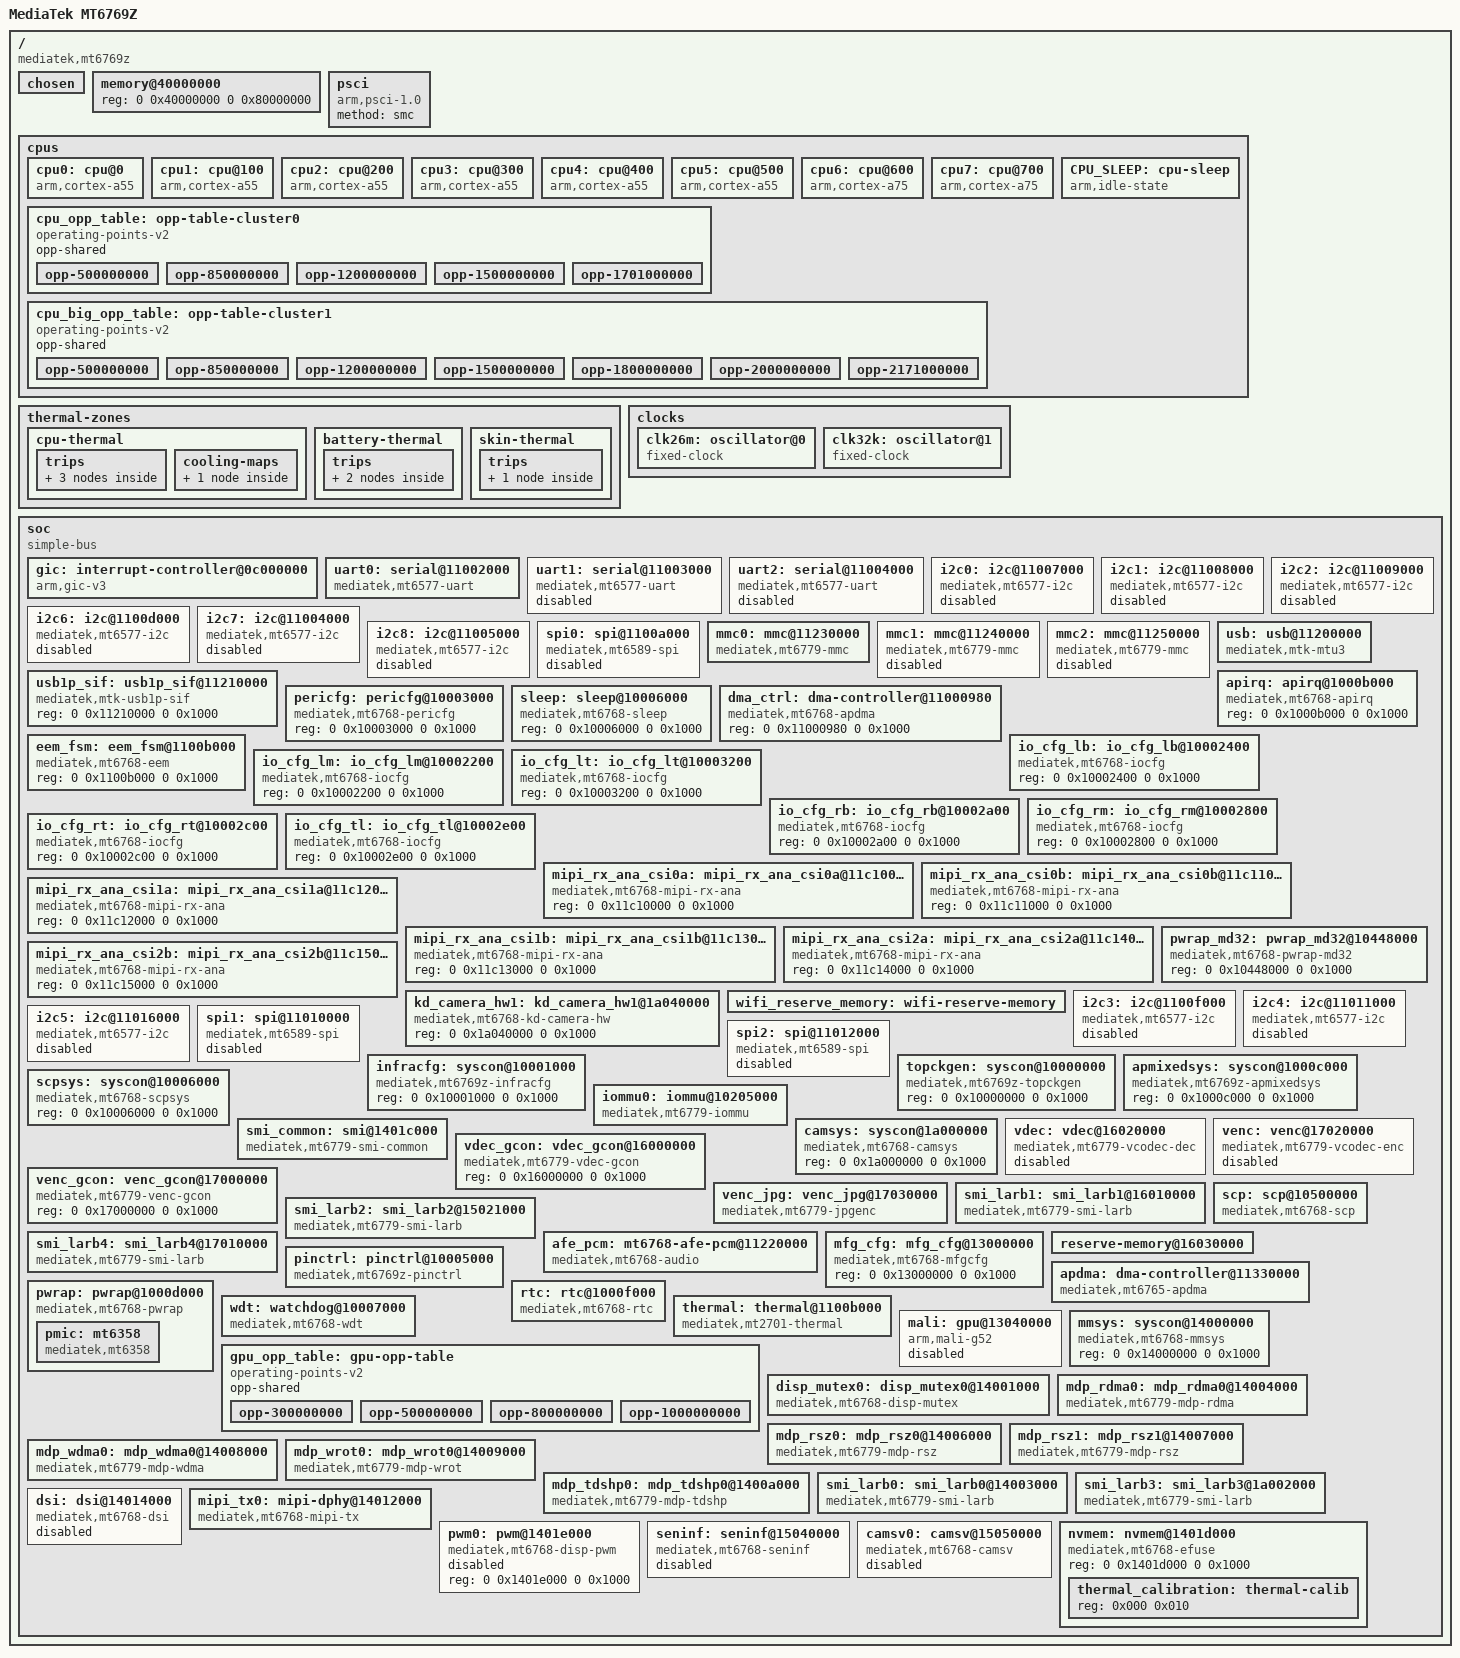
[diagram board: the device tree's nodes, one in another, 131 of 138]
// SPDX-License-Identifier: GPL-2.0
/*
 * MediaTek MT6768/MT6769/MT6769Z SoC device tree source include
 */

#include <dt-bindings/interrupt-controller/arm-gic.h>
#include <dt-bindings/interrupt-controller/irq.h>
#include <dt-bindings/clock/mt6769-clk.h>
#include <dt-bindings/gpio/gpio.h>
#include <dt-bindings/thermal/thermal.h>

/ {
	model = "MediaTek MT6769Z";
	compatible = "mediatek,mt6769z", "mediatek,mt6769", "mediatek,mt6768";
	interrupt-parent = <&gic>;
	#address-cells = <2>;
	#size-cells = <2>;

	chosen {
		bootargs = "console=ttyS0,921600n1 earlycon=uart8250,mmio32,0x11002000,921600n8";
		stdout-path = "uart0:921600n8";
	};

	memory@40000000 {
		device_type = "memory";
		reg = <0 0x40000000 0 0x80000000>;
	};

	psci {
		compatible = "arm,psci-1.0";
		method = "smc";
	};

	cpus {
		#address-cells = <1>;
		#size-cells = <0>;

		cpu0: cpu@0 {
			device_type = "cpu";
			compatible = "arm,cortex-a55";
			reg = <0x000>;
			enable-method = "psci";
			cpu-idle-states = <&CPU_SLEEP>;
			operating-points-v2 = <&cpu_opp_table>;
			#cooling-cells = <2>;
		};
		cpu1: cpu@100 {
			device_type = "cpu";
			compatible = "arm,cortex-a55";
			reg = <0x100>;
			enable-method = "psci";
			cpu-idle-states = <&CPU_SLEEP>;
			operating-points-v2 = <&cpu_opp_table>;
			#cooling-cells = <2>;
		};
		cpu2: cpu@200 {
			device_type = "cpu";
			compatible = "arm,cortex-a55";
			reg = <0x200>;
			enable-method = "psci";
			cpu-idle-states = <&CPU_SLEEP>;
			operating-points-v2 = <&cpu_opp_table>;
			#cooling-cells = <2>;
		};
		cpu3: cpu@300 {
			device_type = "cpu";
			compatible = "arm,cortex-a55";
			reg = <0x300>;
			enable-method = "psci";
			cpu-idle-states = <&CPU_SLEEP>;
			operating-points-v2 = <&cpu_opp_table>;
			#cooling-cells = <2>;
		};
		cpu4: cpu@400 {
			device_type = "cpu";
			compatible = "arm,cortex-a55";
			reg = <0x400>;
			enable-method = "psci";
			cpu-idle-states = <&CPU_SLEEP>;
			operating-points-v2 = <&cpu_opp_table>;
			#cooling-cells = <2>;
		};
		cpu5: cpu@500 {
			device_type = "cpu";
			compatible = "arm,cortex-a55";
			reg = <0x500>;
			enable-method = "psci";
			cpu-idle-states = <&CPU_SLEEP>;
			operating-points-v2 = <&cpu_opp_table>;
			#cooling-cells = <2>;
		};
		cpu6: cpu@600 {
			device_type = "cpu";
			compatible = "arm,cortex-a75";
			reg = <0x600>;
			enable-method = "psci";
			cpu-idle-states = <&CPU_SLEEP>;
			operating-points-v2 = <&cpu_big_opp_table>;
			#cooling-cells = <2>;
		};
		cpu7: cpu@700 {
			device_type = "cpu";
			compatible = "arm,cortex-a75";
			reg = <0x700>;
			enable-method = "psci";
			cpu-idle-states = <&CPU_SLEEP>;
			operating-points-v2 = <&cpu_big_opp_table>;
			#cooling-cells = <2>;
		};

		cpu_opp_table: opp-table-cluster0 {
			compatible = "operating-points-v2";
			opp-shared;

			opp-500000000 {
				opp-hz = /bits/ 64 <500000000>;
				opp-microvolt = <850000>;
			};
			opp-850000000 {
				opp-hz = /bits/ 64 <850000000>;
				opp-microvolt = <900000>;
			};
			opp-1200000000 {
				opp-hz = /bits/ 64 <1200000000>;
				opp-microvolt = <950000>;
			};
			opp-1500000000 {
				opp-hz = /bits/ 64 <1500000000>;
				opp-microvolt = <1000000>;
			};
			opp-1701000000 {
				opp-hz = /bits/ 64 <1701000000>;
				opp-microvolt = <1050000>;
			};
		};

		cpu_big_opp_table: opp-table-cluster1 {
			compatible = "operating-points-v2";
			opp-shared;

			opp-500000000 {
				opp-hz = /bits/ 64 <500000000>;
				opp-microvolt = <850000>;
			};
			opp-850000000 {
				opp-hz = /bits/ 64 <850000000>;
				opp-microvolt = <900000>;
			};
			opp-1200000000 {
				opp-hz = /bits/ 64 <1200000000>;
				opp-microvolt = <950000>;
			};
			opp-1500000000 {
				opp-hz = /bits/ 64 <1500000000>;
				opp-microvolt = <1000000>;
			};
			opp-1800000000 {
				opp-hz = /bits/ 64 <1800000000>;
				opp-microvolt = <1050000>;
			};
			opp-2000000000 {
				opp-hz = /bits/ 64 <2000000000>;
				opp-microvolt = <1100000>;
			};
			opp-2171000000 {
				opp-hz = /bits/ 64 <2171000000>;
				opp-microvolt = <1150000>;
			};
		};

		CPU_SLEEP: cpu-sleep {
			compatible = "arm,idle-state";
			arm,psci-suspend-param = <0x00000001>;
			entry-latency-us = <600>;
			exit-latency-us = <600>;
			min-residency-us = <1200>;
		};
	};

	thermal-zones {
		cpu-thermal {
			polling-delay-passive = <250>;
			polling-delay = <1000>;
			thermal-sensors = <&thermal 0>;

			trips {
				cpu_alert0: cpu-alert0 {
					temperature = <70000>;
					hysteresis = <2000>;
					type = "passive";
				};
				cpu_alert1: cpu-alert1 {
					temperature = <85000>;
					hysteresis = <2000>;
					type = "passive";
				};
				cpu_crit: cpu-crit {
					temperature = <115000>;
					hysteresis = <2000>;
					type = "critical";
				};
			};

			cooling-maps {
				map0 {
					trip = <&cpu_alert0>;
					cooling-device = <&cpu0 THERMAL_NO_LIMIT THERMAL_NO_LIMIT>,
							 <&cpu6 THERMAL_NO_LIMIT THERMAL_NO_LIMIT>;
				};
			};
		};

		battery-thermal {
			polling-delay-passive = <250>;
			polling-delay = <1000>;
			thermal-sensors = <&thermal 1>;

			trips {
				battery_alert: battery-alert {
					temperature = <60000>;
					hysteresis = <2000>;
					type = "passive";
				};
				battery_crit: battery-crit {
					temperature = <70000>;
					hysteresis = <2000>;
					type = "critical";
				};
			};
		};

		skin-thermal {
			polling-delay-passive = <500>;
			polling-delay = <2000>;
			thermal-sensors = <&thermal 2>;

			trips {
				skin_alert: skin-alert {
					temperature = <50000>;
					hysteresis = <2000>;
					type = "passive";
				};
			};
		};
	};

	clocks {
		clk26m: oscillator@0 {
			compatible = "fixed-clock";
			#clock-cells = <0>;
			clock-frequency = <26000000>;
			clock-output-names = "clk26m";
		};
		clk32k: oscillator@1 {
			compatible = "fixed-clock";
			#clock-cells = <0>;
			clock-frequency = <32768>;
			clock-output-names = "clk32k";
		};
	};

	soc {
		compatible = "simple-bus";
		#address-cells = <2>;
		#size-cells = <2>;
		ranges;

		gic: interrupt-controller@0c000000 {
			compatible = "arm,gic-v3";
			reg = <0 0x0c000000 0 0x40000>,
			      <0 0x0c040000 0 0x200000>;
			interrupts = <GIC_PPI 9 IRQ_TYPE_LEVEL_HIGH>;
			interrupt-controller;
			#interrupt-cells = <3>;
		};

		uart0: serial@11002000 {
			compatible = "mediatek,mt6577-uart";
			reg = <0 0x11002000 0 0x1000>;
			interrupts = <GIC_SPI 91 IRQ_TYPE_LEVEL_LOW>;
			clocks = <&infracfg CLK_INFRA_UART0>;
			clock-names = "uart";
			status = "okay";
		};

		uart1: serial@11003000 {
			compatible = "mediatek,mt6577-uart";
			reg = <0 0x11003000 0 0x1000>;
			interrupts = <GIC_SPI 92 IRQ_TYPE_LEVEL_LOW>;
			status = "disabled";
		};

		uart2: serial@11004000 {
			compatible = "mediatek,mt6577-uart";
			reg = <0 0x11004000 0 0x1000>;
			interrupts = <GIC_SPI 93 IRQ_TYPE_LEVEL_LOW>;
			status = "disabled";
		};

		i2c0: i2c@11007000 {
			compatible = "mediatek,mt6577-i2c";
			reg = <0 0x11007000 0 0x1000>,
			      <0 0x11c20000 0 0x1000>;
			interrupts = <GIC_SPI 44 IRQ_TYPE_LEVEL_LOW>;
			clocks = <&clk26m>, <&clk26m>;
			clock-names = "main", "dma";
			#address-cells = <1>;
			#size-cells = <0>;
			status = "disabled";
		};

		i2c1: i2c@11008000 {
			compatible = "mediatek,mt6577-i2c";
			reg = <0 0x11008000 0 0x1000>,
			      <0 0x11c30000 0 0x1000>;
			interrupts = <GIC_SPI 45 IRQ_TYPE_LEVEL_LOW>;
			clocks = <&clk26m>, <&clk26m>;
			clock-names = "main", "dma";
			#address-cells = <1>;
			#size-cells = <0>;
			status = "disabled";
		};

		i2c2: i2c@11009000 {
			compatible = "mediatek,mt6577-i2c";
			reg = <0 0x11009000 0 0x1000>,
			      <0 0x11c40000 0 0x1000>;
			interrupts = <GIC_SPI 46 IRQ_TYPE_LEVEL_LOW>;
			clocks = <&clk26m>, <&clk26m>;
			clock-names = "main", "dma";
			#address-cells = <1>;
			#size-cells = <0>;
			status = "disabled";
		};

		i2c6: i2c@1100d000 {
			compatible = "mediatek,mt6577-i2c";
			reg = <0 0x1100d000 0 0x1000>,
			      <0 0x11c50000 0 0x1000>;
			interrupts = <GIC_SPI 47 IRQ_TYPE_LEVEL_LOW>;
			clocks = <&clk26m>, <&clk26m>;
			clock-names = "main", "dma";
			#address-cells = <1>;
			#size-cells = <0>;
			status = "disabled";
		};

		i2c7: i2c@11004000 {
			compatible = "mediatek,mt6577-i2c";
			reg = <0 0x11004000 0 0x1000>;
			interrupts = <GIC_SPI 48 IRQ_TYPE_LEVEL_LOW>;
			clocks = <&clk26m>;
			clock-names = "main";
			#address-cells = <1>;
			#size-cells = <0>;
			status = "disabled";
		};

		i2c8: i2c@11005000 {
			compatible = "mediatek,mt6577-i2c";
			reg = <0 0x11005000 0 0x1000>;
			interrupts = <GIC_SPI 49 IRQ_TYPE_LEVEL_LOW>;
			clocks = <&clk26m>;
			clock-names = "main";
			#address-cells = <1>;
			#size-cells = <0>;
			status = "disabled";
		};

		spi0: spi@1100a000 {
			compatible = "mediatek,mt6589-spi";
			reg = <0 0x1100a000 0 0x1000>;
			interrupts = <GIC_SPI 111 IRQ_TYPE_LEVEL_LOW>;
			clocks = <&clk26m>;
			clock-names = "main";
			#address-cells = <1>;
			#size-cells = <0>;
			status = "disabled";
		};

		mmc0: mmc@11230000 {
			compatible = "mediatek,mt6779-mmc", "mediatek,mt2712-mmc";
			reg = <0 0x11230000 0 0x1000>,
			      <0 0x11c20000 0 0x1000>;
			interrupts = <GIC_SPI 74 IRQ_TYPE_LEVEL_LOW>;
			clocks = <&clk26m>, <&clk26m>;
			clock-names = "source", "hclk";
			status = "okay";
		};

		mmc1: mmc@11240000 {
			compatible = "mediatek,mt6779-mmc", "mediatek,mt2712-mmc";
			reg = <0 0x11240000 0 0x1000>,
			      <0 0x11c30000 0 0x1000>;
			interrupts = <GIC_SPI 75 IRQ_TYPE_LEVEL_LOW>;
			clocks = <&clk26m>, <&clk26m>;
			clock-names = "source", "hclk";
			status = "disabled";
		};

		mmc2: mmc@11250000 {
			compatible = "mediatek,mt6779-mmc", "mediatek,mt2712-mmc";
			reg = <0 0x11250000 0 0x1000>,
			      <0 0x11c40000 0 0x1000>;
			interrupts = <GIC_SPI 76 IRQ_TYPE_LEVEL_LOW>;
			clocks = <&clk26m>, <&clk26m>;
			clock-names = "source", "hclk";
			status = "disabled";
		};

		usb: usb@11200000 {
			compatible = "mediatek,mtk-mtu3";
			reg = <0 0x11200000 0 0x3000>;
			interrupts = <GIC_SPI 64 IRQ_TYPE_LEVEL_LOW>;
			clocks = <&clk26m>, <&clk26m>;
			clock-names = "sys_ck", "ref_ck";
			dr_mode = "otg";
			status = "okay";
		};

		/* USB 1.1 PHY interface */
		usb1p_sif: usb1p_sif@11210000 {
			compatible = "mediatek,mtk-usb1p-sif";
			reg = <0 0x11210000 0 0x1000>;
		};

		/* AP IRQ - peripheral interrupt controller */
		apirq: apirq@1000b000 {
			compatible = "mediatek,mt6768-apirq", "syscon";
			reg = <0 0x1000b000 0 0x1000>;
		};

		/* Peripheral config - clock/power gating */
		pericfg: pericfg@10003000 {
			compatible = "mediatek,mt6768-pericfg", "syscon";
			reg = <0 0x10003000 0 0x1000>;
		};

		/* Sleep controller - suspend/resume */
		sleep: sleep@10006000 {
			compatible = "mediatek,mt6768-sleep", "syscon";
			reg = <0 0x10006000 0 0x1000>;
		};

		/* APDMA controller */
		dma_ctrl: dma-controller@11000980 {
			compatible = "mediatek,mt6768-apdma", "syscon";
			reg = <0 0x11000980 0 0x1000>;
		};

		/* EEM - Enhanced Error Management (thermal/DVFS) */
		eem_fsm: eem_fsm@1100b000 {
			compatible = "mediatek,mt6768-eem", "syscon";
			reg = <0 0x1100b000 0 0x1000>;
		};

		/* IO config - voltage level shifters */
		io_cfg_lb: io_cfg_lb@10002400 {
			compatible = "mediatek,mt6768-iocfg", "syscon";
			reg = <0 0x10002400 0 0x1000>;
		};

		io_cfg_lm: io_cfg_lm@10002200 {
			compatible = "mediatek,mt6768-iocfg", "syscon";
			reg = <0 0x10002200 0 0x1000>;
		};

		io_cfg_lt: io_cfg_lt@10003200 {
			compatible = "mediatek,mt6768-iocfg", "syscon";
			reg = <0 0x10003200 0 0x1000>;
		};

		io_cfg_rb: io_cfg_rb@10002a00 {
			compatible = "mediatek,mt6768-iocfg", "syscon";
			reg = <0 0x10002a00 0 0x1000>;
		};

		io_cfg_rm: io_cfg_rm@10002800 {
			compatible = "mediatek,mt6768-iocfg", "syscon";
			reg = <0 0x10002800 0 0x1000>;
		};

		io_cfg_rt: io_cfg_rt@10002c00 {
			compatible = "mediatek,mt6768-iocfg", "syscon";
			reg = <0 0x10002c00 0 0x1000>;
		};

		io_cfg_tl: io_cfg_tl@10002e00 {
			compatible = "mediatek,mt6768-iocfg", "syscon";
			reg = <0 0x10002e00 0 0x1000>;
		};

		/* MIPI CSI PHY - camera sensor interface */
		mipi_rx_ana_csi0a: mipi_rx_ana_csi0a@11c10000 {
			compatible = "mediatek,mt6768-mipi-rx-ana";
			reg = <0 0x11c10000 0 0x1000>;
		};

		mipi_rx_ana_csi0b: mipi_rx_ana_csi0b@11c11000 {
			compatible = "mediatek,mt6768-mipi-rx-ana";
			reg = <0 0x11c11000 0 0x1000>;
		};

		mipi_rx_ana_csi1a: mipi_rx_ana_csi1a@11c12000 {
			compatible = "mediatek,mt6768-mipi-rx-ana";
			reg = <0 0x11c12000 0 0x1000>;
		};

		mipi_rx_ana_csi1b: mipi_rx_ana_csi1b@11c13000 {
			compatible = "mediatek,mt6768-mipi-rx-ana";
			reg = <0 0x11c13000 0 0x1000>;
		};

		mipi_rx_ana_csi2a: mipi_rx_ana_csi2a@11c14000 {
			compatible = "mediatek,mt6768-mipi-rx-ana";
			reg = <0 0x11c14000 0 0x1000>;
		};

		mipi_rx_ana_csi2b: mipi_rx_ana_csi2b@11c15000 {
			compatible = "mediatek,mt6768-mipi-rx-ana";
			reg = <0 0x11c15000 0 0x1000>;
		};

		/* Camera HW interface */
		kd_camera_hw1: kd_camera_hw1@1a040000 {
			compatible = "mediatek,mt6768-kd-camera-hw";
			reg = <0 0x1a040000 0 0x1000>;
		};

		/* WiFi reserve memory for firmware */
		wifi_reserve_memory: wifi-reserve-memory {
			reg = <0 0x18000000 0 0x200000>;
			no-map;
		};

		/* PWRAP sub-nodes */
		pwrap_md32: pwrap_md32@10448000 {
			compatible = "mediatek,mt6768-pwrap-md32";
			reg = <0 0x10448000 0 0x1000>;
		};

		/* I2C3, I2C4, I2C5 */
		i2c3: i2c@1100f000 {
			compatible = "mediatek,mt6577-i2c";
			reg = <0 0x1100f000 0 0x1000>,
			      <0 0x11c60000 0 0x1000>;
			interrupts = <GIC_SPI 50 IRQ_TYPE_LEVEL_LOW>;
			clocks = <&clk26m>, <&clk26m>;
			clock-names = "main", "dma";
			#address-cells = <1>;
			#size-cells = <0>;
			status = "disabled";
		};

		i2c4: i2c@11011000 {
			compatible = "mediatek,mt6577-i2c";
			reg = <0 0x11011000 0 0x1000>,
			      <0 0x11c70000 0 0x1000>;
			interrupts = <GIC_SPI 51 IRQ_TYPE_LEVEL_LOW>;
			clocks = <&clk26m>, <&clk26m>;
			clock-names = "main", "dma";
			#address-cells = <1>;
			#size-cells = <0>;
			status = "disabled";
		};

		i2c5: i2c@11016000 {
			compatible = "mediatek,mt6577-i2c";
			reg = <0 0x11016000 0 0x1000>,
			      <0 0x11c80000 0 0x1000>;
			interrupts = <GIC_SPI 52 IRQ_TYPE_LEVEL_LOW>;
			clocks = <&clk26m>, <&clk26m>;
			clock-names = "main", "dma";
			#address-cells = <1>;
			#size-cells = <0>;
			status = "disabled";
		};

		/* Additional SPI buses */
		spi1: spi@11010000 {
			compatible = "mediatek,mt6589-spi";
			reg = <0 0x11010000 0 0x1000>;
			interrupts = <GIC_SPI 112 IRQ_TYPE_LEVEL_LOW>;
			clocks = <&clk26m>;
			clock-names = "main";
			#address-cells = <1>;
			#size-cells = <0>;
			status = "disabled";
		};

		spi2: spi@11012000 {
			compatible = "mediatek,mt6589-spi";
			reg = <0 0x11012000 0 0x1000>;
			interrupts = <GIC_SPI 113 IRQ_TYPE_LEVEL_LOW>;
			clocks = <&clk26m>;
			clock-names = "main";
			#address-cells = <1>;
			#size-cells = <0>;
			status = "disabled";
		};

		infracfg: syscon@10001000 {
			compatible = "mediatek,mt6769z-infracfg", "mediatek,mt6769-infracfg", "mediatek,mt6768-infracfg",
				     "syscon";
			reg = <0 0x10001000 0 0x1000>;
		};

		topckgen: syscon@10000000 {
			compatible = "mediatek,mt6769z-topckgen", "mediatek,mt6769-topckgen", "mediatek,mt6768-topckgen", "syscon";
			reg = <0 0x10000000 0 0x1000>;
		};

		apmixedsys: syscon@1000c000 {
			compatible = "mediatek,mt6769z-apmixedsys", "mediatek,mt6769-apmixedsys", "mediatek,mt6768-apmixedsys", "syscon";
			reg = <0 0x1000c000 0 0x1000>;
		};

		scpsys: syscon@10006000 {
			compatible = "mediatek,mt6768-scpsys", "syscon";
			reg = <0 0x10006000 0 0x1000>;
		};

		/* IOMMU - memory management */
		iommu0: iommu@10205000 {
			compatible = "mediatek,mt6779-iommu", "mediatek,mt6779-m4u";
			reg = <0 0x10205000 0 0x1000>;
			interrupts = <GIC_SPI 134 IRQ_TYPE_LEVEL_LOW>;
			#iommu-cells = <1>;
		};

		/* SMI - Smart Multimedia Interface */
		smi_common: smi@1401c000 {
			compatible = "mediatek,mt6779-smi-common", "mediatek,mt6765-smi-common";
			reg = <0 0x1401c000 0 0x1000>;
			clocks = <&clk26m>, <&clk26m>;
			clock-names = "apb", "smi";
		};

		/* CAMSYS - Camera System */
		camsys: syscon@1a000000 {
			compatible = "mediatek,mt6768-camsys", "syscon";
			reg = <0 0x1a000000 0 0x1000>;
		};

		/* VDEC - Video Decoder */
		vdec: vdec@16020000 {
			compatible = "mediatek,mt6779-vcodec-dec", "mediatek,mt6779-vdec";
			reg = <0 0x16020000 0 0x1000>;
			interrupts = <GIC_SPI 200 IRQ_TYPE_LEVEL_LOW>;
			clocks = <&clk26m>;
			clock-names = "vdec";
			iommus = <&iommu0 7>;
			mediatek,larb = <&smi_larb1>;
			status = "disabled";
		};

		vdec_gcon: vdec_gcon@16000000 {
			compatible = "mediatek,mt6779-vdec-gcon", "syscon";
			reg = <0 0x16000000 0 0x1000>;
		};

		/* VENC - Video Encoder */
		venc: venc@17020000 {
			compatible = "mediatek,mt6779-vcodec-enc", "mediatek,mt6779-venc";
			reg = <0 0x17020000 0 0x1000>;
			interrupts = <GIC_SPI 204 IRQ_TYPE_LEVEL_LOW>;
			clocks = <&clk26m>;
			clock-names = "venc";
			iommus = <&iommu0 9>;
			mediatek,larb = <&smi_larb2>;
			status = "disabled";
		};

		venc_gcon: venc_gcon@17000000 {
			compatible = "mediatek,mt6779-venc-gcon", "syscon";
			reg = <0 0x17000000 0 0x1000>;
		};

		/* VENC JPEG */
		venc_jpg: venc_jpg@17030000 {
			compatible = "mediatek,mt6779-jpgenc";
			reg = <0 0x17030000 0 0x1000>;
			interrupts = <GIC_SPI 206 IRQ_TYPE_LEVEL_LOW>;
			clocks = <&clk26m>;
			clock-names = "jpgenc";
		};

		/* SMI LARBs for VDEC/VENC */
		smi_larb1: smi_larb1@16010000 {
			compatible = "mediatek,mt6779-smi-larb", "mediatek,mt6765-smi-larb";
			reg = <0 0x16010000 0 0x1000>;
			clocks = <&clk26m>;
			clock-names = "larb";
			iommus = <&iommu0 2>;
		};

		smi_larb2: smi_larb2@15021000 {
			compatible = "mediatek,mt6779-smi-larb", "mediatek,mt6765-smi-larb";
			reg = <0 0x15021000 0 0x1000>;
			clocks = <&clk26m>;
			clock-names = "larb";
			iommus = <&iommu0 3>;
		};

		smi_larb4: smi_larb4@17010000 {
			compatible = "mediatek,mt6779-smi-larb", "mediatek,mt6765-smi-larb";
			reg = <0 0x17010000 0 0x1000>;
			clocks = <&clk26m>;
			clock-names = "larb";
			iommus = <&iommu0 4>;
		};

		/* SCP - Sensor Communication Processor */
		scp: scp@10500000 {
			compatible = "mediatek,mt6768-scp", "mediatek,scp";
			reg = <0 0x10500000 0 0x20000>;
			clocks = <&clk26m>;
			clock-names = "scp";
			interrupts = <GIC_SPI 188 IRQ_TYPE_LEVEL_HIGH>;
			sram_size = <0x80000>;
			status = "okay";
		};

		/* AFE PCM - Audio Front End */
		afe_pcm: mt6768-afe-pcm@11220000 {
			compatible = "mediatek,mt6768-audio";
			reg = <0 0x11220000 0 0x10000>;
			interrupts = <GIC_SPI 140 IRQ_TYPE_LEVEL_LOW>;
			clocks = <&clk26m>;
			clock-names = "audio";
			status = "okay";
		};

		/* MFG - 3D Graphics config */
		mfg_cfg: mfg_cfg@13000000 {
			compatible = "mediatek,mt6768-mfgcfg", "syscon";
			reg = <0 0x13000000 0 0x1000>;
		};

		/* WiFi reserve memory */
		reserve-memory@16030000 {
			reg = <0 0x16030000 0 0x100000>;
			no-map;
		};

		/* APDMA - audio DMA controller */
		apdma: dma-controller@11330000 {
			compatible = "mediatek,mt6765-apdma", "mediatek,mt2701-apdma";
			reg = <0 0x11330000 0 0x1000>;
			interrupts = <GIC_SPI 123 IRQ_TYPE_LEVEL_LOW>;
			#dma-cells = <2>;
			clocks = <&clk26m>, <&clk26m>;
			clock-names = "apdma", "apdma_mux";
			status = "okay";
		};

		pinctrl: pinctrl@10005000 {
			compatible = "mediatek,mt6769z-pinctrl", "mediatek,mt6769-pinctrl", "mediatek,mt6768-pinctrl";
			reg = <0 0x10005000 0 0x1000>;
			gpio-controller;
			gpio-ranges = <&pinctrl 0 0 187>;
			#gpio-cells = <2>;
			interrupt-controller;
			interrupts = <GIC_SPI 186 IRQ_TYPE_LEVEL_HIGH>;
			#interrupt-cells = <2>;
		};

		pwrap: pwrap@1000d000 {
			compatible = "mediatek,mt6768-pwrap";
			reg = <0 0x1000d000 0 0x1000>;
			interrupts = <GIC_SPI 194 IRQ_TYPE_LEVEL_HIGH>;

			pmic: mt6358 {
				compatible = "mediatek,mt6358";
				interrupt-controller;
				#interrupt-cells = <2>;
				interrupts = <144 IRQ_TYPE_LEVEL_HIGH>;
			};
		};

		rtc: rtc@1000f000 {
			compatible = "mediatek,mt6768-rtc", "mediatek,mt6397-rtc";
			reg = <0 0x1000f000 0 0x1000>;
			interrupts = <GIC_SPI 137 IRQ_TYPE_LEVEL_LOW>;
		};

		wdt: watchdog@10007000 {
			compatible = "mediatek,mt6768-wdt", "mediatek,mt6589-wdt";
			reg = <0 0x10007000 0 0x1000>;
			interrupts = <GIC_SPI 156 IRQ_TYPE_LEVEL_LOW>;
			timeout-sec = <10>;
			status = "okay";
		};

		thermal: thermal@1100b000 {
			compatible = "mediatek,mt2701-thermal";
			reg = <0 0x1100b000 0 0x1000>;
			interrupts = <GIC_SPI 53 IRQ_TYPE_LEVEL_LOW>;
			#thermal-sensor-cells = <1>;
			nvmem-cells = <&thermal_calibration>;
			nvmem-cell-names = "calibration-data";
			status = "okay";
		};

		mali: gpu@13040000 {
			compatible = "arm,mali-g52", "arm,mali-bifrost";
			reg = <0 0x13040000 0 0x10000>;
			interrupts = <GIC_SPI 220 IRQ_TYPE_LEVEL_HIGH>,
				     <GIC_SPI 221 IRQ_TYPE_LEVEL_HIGH>,
				     <GIC_SPI 222 IRQ_TYPE_LEVEL_HIGH>;
			interrupt-names = "job", "mmu", "gpu";
			clocks = <&topckgen CLK_TOP_MMPLL>;
			clock-names = "gpu";
			operating-points-v2 = <&gpu_opp_table>;
			status = "disabled";
		};

		gpu_opp_table: gpu-opp-table {
			compatible = "operating-points-v2";
			opp-shared;

			opp-300000000 {
				opp-hz = /bits/ 64 <300000000>;
				opp-microvolt = <800000>;
			};
			opp-500000000 {
				opp-hz = /bits/ 64 <500000000>;
				opp-microvolt = <900000>;
			};
			opp-800000000 {
				opp-hz = /bits/ 64 <800000000>;
				opp-microvolt = <1000000>;
			};
			opp-1000000000 {
				opp-hz = /bits/ 64 <1000000000>;
				opp-microvolt = <1100000>;
			};
		};

		mmsys: syscon@14000000 {
			compatible = "mediatek,mt6768-mmsys", "syscon";
			reg = <0 0x14000000 0 0x1000>;
		};

		/* Display Mutex */
		disp_mutex0: disp_mutex0@14001000 {
			compatible = "mediatek,mt6768-disp-mutex", "mediatek,mt6779-disp-mutex";
			reg = <0 0x14001000 0 0x1000>;
			interrupts = <GIC_SPI 195 IRQ_TYPE_LEVEL_LOW>;
		};

		/* MDP - Media Data Path */
		mdp_rdma0: mdp_rdma0@14004000 {
			compatible = "mediatek,mt6779-mdp-rdma", "mediatek,mt6779-mdp_rdma0";
			reg = <0 0x14004000 0 0x1000>;
			clocks = <&mmsys CLK_MM_DISP_RDMA0>;
			interrupts = <GIC_SPI 196 IRQ_TYPE_LEVEL_LOW>;
			iommus = <&iommu0 15>;
		};

		mdp_rsz0: mdp_rsz0@14006000 {
			compatible = "mediatek,mt6779-mdp-rsz", "mediatek,mt6779-mdp_rsz0";
			reg = <0 0x14006000 0 0x1000>;
			clocks = <&clk26m>;
		};

		mdp_rsz1: mdp_rsz1@14007000 {
			compatible = "mediatek,mt6779-mdp-rsz", "mediatek,mt6779-mdp_rsz1";
			reg = <0 0x14007000 0 0x1000>;
			clocks = <&clk26m>;
		};

		mdp_wdma0: mdp_wdma0@14008000 {
			compatible = "mediatek,mt6779-mdp-wdma", "mediatek,mt6779-mdp_wdma0";
			reg = <0 0x14008000 0 0x1000>;
			clocks = <&clk26m>;
			interrupts = <GIC_SPI 197 IRQ_TYPE_LEVEL_LOW>;
			iommus = <&iommu0 16>;
		};

		mdp_wrot0: mdp_wrot0@14009000 {
			compatible = "mediatek,mt6779-mdp-wrot", "mediatek,mt6779-mdp_wrot0";
			reg = <0 0x14009000 0 0x1000>;
			clocks = <&clk26m>;
			interrupts = <GIC_SPI 198 IRQ_TYPE_LEVEL_LOW>;
			iommus = <&iommu0 17>;
		};

		mdp_tdshp0: mdp_tdshp0@1400a000 {
			compatible = "mediatek,mt6779-mdp-tdshp", "mediatek,mt6779-mdp_tdshp0";
			reg = <0 0x1400a000 0 0x1000>;
			clocks = <&clk26m>;
		};

		/* SMI - Smart Multimedia Interface */
		smi_larb0: smi_larb0@14003000 {
			compatible = "mediatek,mt6779-smi-larb", "mediatek,mt6765-smi-larb";
			reg = <0 0x14003000 0 0x1000>;
			clocks = <&clk26m>;
			clock-names = "apb";
			mediatek,smi = <&smi_common>;
			iommus = <&iommu0 0>;
		};

		smi_larb3: smi_larb3@1a002000 {
			compatible = "mediatek,mt6779-smi-larb", "mediatek,mt6765-smi-larb";
			reg = <0 0x1a002000 0 0x1000>;
			clocks = <&clk26m>;
			clock-names = "smi";
			iommus = <&iommu0 5>;
		};

		dsi: dsi@14014000 {
			compatible = "mediatek,mt6768-dsi", "mediatek,mt6779-dsi";
			reg = <0 0x14014000 0 0x1000>,
			      <0 0x14015000 0 0x1000>;
			interrupts = <GIC_SPI 210 IRQ_TYPE_LEVEL_LOW>;
			phys = <&mipi_tx0>;
			phy-names = "dphy";
			status = "disabled";
		};

		mipi_tx0: mipi-dphy@14012000 {
			compatible = "mediatek,mt6768-mipi-tx", "mediatek,mt6779-mipi-tx";
			reg = <0 0x14012000 0 0x1000>;
			clocks = <&clk26m>;
			clock-output-names = "mipitx_dsi_ck";
			#clock-cells = <0>;
			#phy-cells = <0>;
		};

		pwm0: pwm@1401e000 {
			compatible = "mediatek,mt6768-disp-pwm", "mediatek,mt6779-disp-pwm";
			reg = <0 0x1401e000 0 0x1000>;
			#pwm-cells = <2>;
			status = "disabled";
		};

		seninf: seninf@15040000 {
			compatible = "mediatek,mt6768-seninf", "mediatek,mt6779-seninf";
			reg = <0 0x15040000 0 0x4000>;
			interrupts = <GIC_SPI 208 IRQ_TYPE_LEVEL_LOW>;
			status = "disabled";
		};

		camsv0: camsv@15050000 {
			compatible = "mediatek,mt6768-camsv", "mediatek,mt6779-camsv";
			reg = <0 0x15050000 0 0x1000>;
			interrupts = <GIC_SPI 209 IRQ_TYPE_LEVEL_LOW>;
			status = "disabled";
		};

		nvmem: nvmem@1401d000 {
			compatible = "mediatek,mt6768-efuse", "mediatek,efuse";
			reg = <0 0x1401d000 0 0x1000>;

			thermal_calibration: thermal-calib {
				reg = <0x000 0x010>;
			};
		};
	};
};
